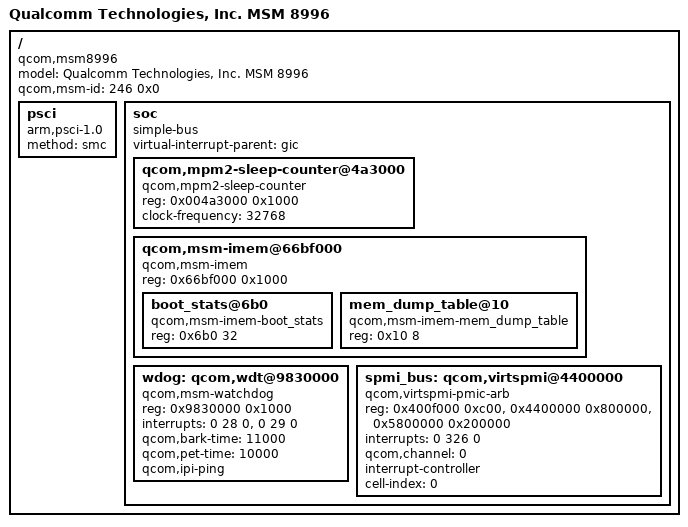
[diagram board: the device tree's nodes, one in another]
/* Copyright (c) 2017-2018, The Linux Foundation. All rights reserved.
 *
 * This program is free software; you can redistribute it and/or modify
 * it under the terms of the GNU General Public License version 2 and
 * only version 2 as published by the Free Software Foundation.
 *
 * This program is distributed in the hope that it will be useful,
 * but WITHOUT ANY WARRANTY; without even the implied warranty of
 * MERCHANTABILITY or FITNESS FOR A PARTICULAR PURPOSE.  See the
 * GNU General Public License for more details.
 */

#include "skeleton64.dtsi"

/ {
	model = "Qualcomm Technologies, Inc. MSM 8996";
	compatible = "qcom,msm8996";
	qcom,msm-id = <246 0x0>;

	psci {
		compatible = "arm,psci-1.0";
		method = "smc";
	};

	soc: soc {
		#address-cells = <1>;
		#size-cells = <1>;
		virtual-interrupt-parent = "gic";
		ranges = <0 0 0 0xffffffff>;
		compatible = "simple-bus";

		qcom,mpm2-sleep-counter@4a3000 {
			compatible = "qcom,mpm2-sleep-counter";
			reg = <0x004a3000 0x1000>;
			clock-frequency = <32768>;
		};

		qcom,msm-imem@66bf000 {
			compatible = "qcom,msm-imem";
			reg = <0x66bf000 0x1000>; /* Address and size of IMEM */
			ranges = <0x0 0x66bf000 0x1000>;
			#address-cells = <1>;
			#size-cells = <1>;

			boot_stats@6b0 {
				compatible = "qcom,msm-imem-boot_stats";
				reg = <0x6b0 32>;
			};

			mem_dump_table@10 {
				compatible = "qcom,msm-imem-mem_dump_table";
				reg = <0x10 8>;
			};
		};

		wdog: qcom,wdt@9830000 {
			compatible = "qcom,msm-watchdog";
			reg = <0x9830000 0x1000>;
			reg-names = "wdt-base";
			interrupts = <0 28 0>, <0 29 0>;
			qcom,bark-time = <11000>;
			qcom,pet-time = <10000>;
			qcom,ipi-ping;
		};

		spmi_bus: qcom,virtspmi@4400000 {
			compatible = "qcom,virtspmi-pmic-arb";
			reg = <0x400f000 0xc00>,
				<0x4400000 0x800000>,
				<0x5800000 0x200000>;
			reg-names = "core", "chnls", "intr";
			interrupt-names = "periph_irq";
			interrupts = <0 326 0>;
			qcom,channel = <0>;
			#address-cells = <2>;
			#size-cells = <0>;
			interrupt-controller;
			#interrupt-cells = <4>;
			cell-index = <0>;
		};
	};
};
